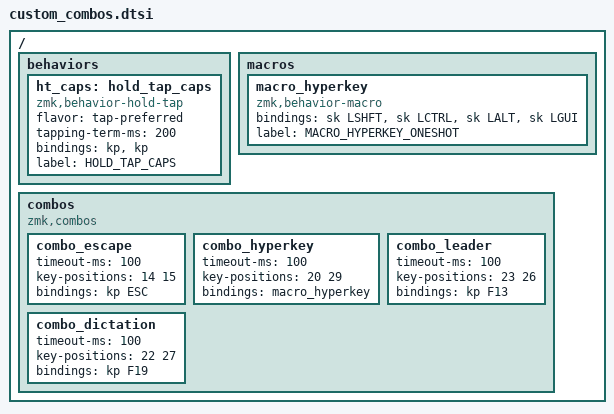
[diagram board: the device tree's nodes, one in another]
// miryoku/custom_combos.dtsi
// Custom ZMK combos, Miryoku-style (split file).
// Keep this minimal & clean; we'll tune positions after a test build.

#include <dt-bindings/zmk/keys.h>

/ {
    behaviors {
        ht_caps: hold_tap_caps {
            compatible = "zmk,behavior-hold-tap";
            #binding-cells = <2>;
            flavor = "tap-preferred";
            tapping-term-ms = <200>;
            bindings = <&kp>, <&kp>;
            label = "HOLD_TAP_CAPS";
        };
    };

    macros {
        macro_hyperkey: macro_hyperkey {
            compatible = "zmk,behavior-macro";
            #binding-cells = <0>;
            bindings = <&sk LSHFT &sk LCTRL &sk LALT &sk LGUI>;
            label = "MACRO_HYPERKEY_ONESHOT";
        };
    };

    combos {
        compatible = "zmk,combos";

        // ESC: G + M (cross-hand, inner home row)
        // Note: Old ZMK fork doesn't support require-prior-idle-ms
        combo_escape {
            timeout-ms = <100>;
            key-positions = <14 15>;
            bindings = <&kp ESC>;
        };

        // Hyper: Z + / (cross-hand, bottom row corners, one-shot)
        combo_hyperkey {
            timeout-ms = <100>;
            key-positions = <20 29>;
            bindings = <&macro_hyperkey>;
        };

        // F13 Leader: D + H (cross-hand, bottom row)
        combo_leader {
            timeout-ms = <100>;
            key-positions = <23 26>;
            bindings = <&kp F13>;
        };

        // F19 Dictation: C + , (cross-hand, home/bottom row)
        combo_dictation {
            timeout-ms = <100>;
            key-positions = <22 27>;
            bindings = <&kp F19>;
        };
    };
};
